# psoc6_01 register map
Vendor: Infineon Technologies; Series: PSOC6_01; File version: 1.0
CPU: CM4 r0p1, little endian, MPU, FPU, VTOR, 3 interrupt priority bits
Registers are 32-bit, read-write, reset 0x0 unless marked. A register's access mark holds for its fields unless they carry their own. Offsets are from the block's base; [hi:lo] are bit positions; 'fields as' and 'values as' point back to an identical list.

## CTBM0 — Continuous Time Block Mini
Base 0x41100000
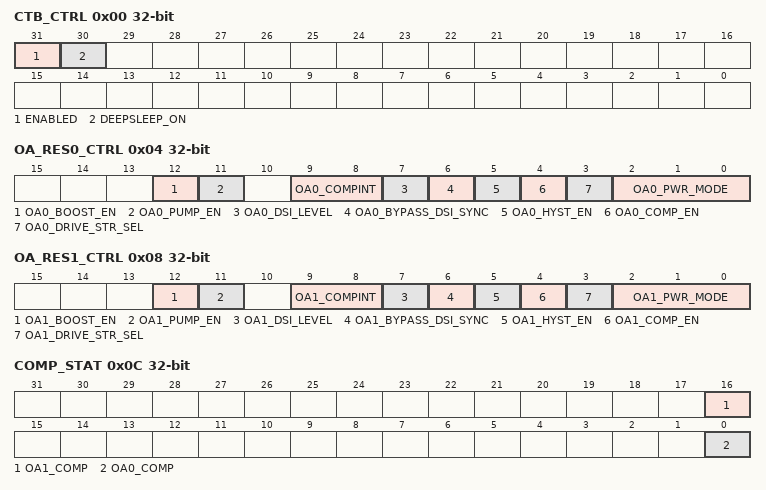
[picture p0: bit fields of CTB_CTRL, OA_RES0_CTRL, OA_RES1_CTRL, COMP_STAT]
0x00 CTB_CTRL — global CTB and power control
  [31] ENABLED — - 0: CTBm disabled (put analog in power down, open all switches) - 1: CTBm enabled
  [30] DEEPSLEEP_ON — - 0: CTBm is disabled during DeepSleep power mode - 1: CTBm remains enabled during DeepSleep power mode (if ENABLED=1)
0x04 OA_RES0_CTRL — Opamp0 and resistor0 control
  [12] OA0_BOOST_EN
  [11] OA0_PUMP_EN
  [9:8] OA0_COMPINT — Opamp comparator edge detect for interrupt and pulse mode of trigger
    0=DISABLE (Disabled, no interrupts will be detected); 1=RISING (Rising edge); 2=FALLING (Falling edge); 3=BOTH (Both rising and falling edges)
  [7] OA0_DSI_LEVEL — Opamp comparator trigger output level : 0=pulse, each time an edge is detected (see OA0_COMPINT) a pulse is sent out on trigger 1=level, trigger output is a synchronized version of the comparator output
  [6] OA0_BYPASS_DSI_SYNC — Opamp bypass comparator output synchronization for trigger output: 0=synchronize (level or pulse), 1=bypass (asynchronous output).
  [5] OA0_HYST_EN — Opamp hysteresis enable. See the device Datasheet for hysteresis specifications.
  [4] OA0_COMP_EN
  [3] OA0_DRIVE_STR_SEL — Opamp output drive strength: 0=1x, 1=10x. See the device Datasheet for exact current ranges and related specifications.This setting sets specific requirements for OA0_BOOST_EN and OA0_COMP_TRIM.
  [2:0] OA0_PWR_MODE — Opamp power level. Reduced power levels also reduce gain-bandwidth (GBW). See the 'Opamp Specifications' table in the device Datasheet for more details.
    0=OFF; 1=LOW (Low power mode (IDD: 350uA, GBW: 1MHz for both 1x/10x)); 2=MEDIUM (Medium power mode (IDD: 600uA, GBW: 3MHz for 1x & 2.5MHz for 10x)); 3=HIGH (High power mode for highest GBW (IDD: 1500uA, GBW: 8MHz for 1x & 6MHz for 10x)); 4=RSVD (N/A); 5=PS_LOW (Power Saver Low power mode (IDD: ~20uA with 1uA bias from AREF, GBW: ~100kHz for 1x/10x, offset correcting IDAC is disabled)); 6=PS_MEDIUM (Power Saver Medium power mode (IDD: ~40uA with 1uA bias from AREF, GBW: ~100kHz for 1x/10x, offset correcting IDAC is enabled)); 7=PS_HIGH (Power Saver Medium power mode (IDD: ~60uA with 1uA bias from AREF, GBW: ~200kHz for 1x/10x, offset correcting IDAC is enabled))
0x08 OA_RES1_CTRL — Opamp1 and resistor1 control
  [12] OA1_BOOST_EN
  [11] OA1_PUMP_EN
  [9:8] OA1_COMPINT — Opamp comparator edge detect for interrupt and pulse mode of trigger
    values as OA_RES0_CTRL.OA0_COMPINT
  [7] OA1_DSI_LEVEL — Opamp comparator trigger output level : 0=pulse, each time an edge is detected (see OA1_COMPINT) a pulse is sent out on trigger 1=level, trigger output is a synchronized version of the comparator output
  [6] OA1_BYPASS_DSI_SYNC — Opamp bypass comparator output synchronization for trigger output: 0=synchronize (level or pulse), 1=bypass (asynchronous output).
  [5] OA1_HYST_EN — Opamp hysteresis enable. See the device Datasheet for hysteresis specifications.
  [4] OA1_COMP_EN
  [3] OA1_DRIVE_STR_SEL — Opamp output drive strength: 0=1x, 1=10x. See the device Datasheet for exact current ranges and related specifications.This setting sets specific requirements for OA1_BOOST_EN and OA1_COMP_TRIM
  [2:0] OA1_PWR_MODE — Opamp power level. Reduced power levels also reduce gain-bandwidth (GBW). See the 'Opamp Specifications' table in the device Datasheet for more details.
0x0C COMP_STAT ro — Comparator status
  [16] OA1_COMP — Opamp1 current comparator status
  [0] OA0_COMP — Opamp0 current comparator status
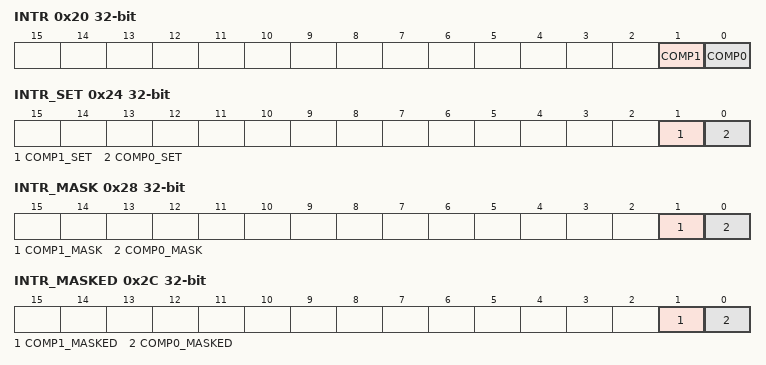
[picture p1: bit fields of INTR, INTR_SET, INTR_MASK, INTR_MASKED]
0x20 INTR — Interrupt request register
  [1] COMP1 — Comparator 1 Interrupt: hardware sets this interrupt when comparator 1 triggers. Write with '1' to clear bit.
  [0] COMP0 — Comparator 0 Interrupt: hardware sets this interrupt when comparator 0 triggers. Write with '1' to clear bit.
0x24 INTR_SET — Interrupt request set register
  [1] COMP1_SET — Write with '1' to set corresponding bit in interrupt request register.
  [0] COMP0_SET — Write with '1' to set corresponding bit in interrupt request register.
0x28 INTR_MASK — Interrupt request mask
  [1] COMP1_MASK — Mask bit for corresponding bit in interrupt request register.
  [0] COMP0_MASK — Mask bit for corresponding bit in interrupt request register.
0x2C INTR_MASKED ro — Interrupt request masked
  [1] COMP1_MASKED — Logical and of corresponding request and mask bits.
  [0] COMP0_MASKED — Logical and of corresponding request and mask bits.
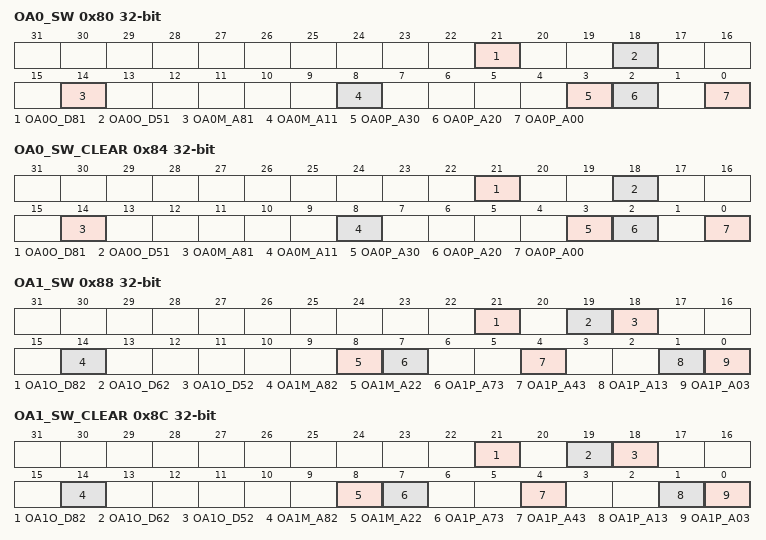
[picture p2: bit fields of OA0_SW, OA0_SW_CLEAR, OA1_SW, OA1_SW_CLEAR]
0x80 OA0_SW — Opamp0 switch control
  [21] OA0O_D81 — Switch that shorts Opamp's 1x and 10x outputs.
  [18] OA0O_D51 — Switch that connects Opamp's output to SARBUS 0.
  [14] OA0M_A81 — Switch that connects Opamp's inverting terminal to Opamp's output for follower mode.
  [8] OA0M_A11 — Switch that connects Opamp's inverting terminal to pin 1 of CTBm port .
  [3] OA0P_A30 — Switch that connects Opamp's non-inverting terminal to pin 6 of CTBm port. Note that this bus can have additional connections to or from the CTDAC. See the Architecture TRM for details.
  [2] OA0P_A20 — Switch that connects Opamp's non-inverting terminal to pin 0 of CTBm port. See the device Datasheet for the location of CTBm port.
  [0] OA0P_A00 — Switch that connects Opamp's non-inverting terminal to AMUXBUS A.
0x84 OA0_SW_CLEAR — Opamp0 switch control clear
  [21] OA0O_D81 — see corresponding bit in OA0_SW
  [18] OA0O_D51 — see corresponding bit in OA0_SW
  [14] OA0M_A81 — see corresponding bit in OA0_SW
  [8] OA0M_A11 — see corresponding bit in OA0_SW
  [3] OA0P_A30 — see corresponding bit in OA0_SW
  [2] OA0P_A20 — see corresponding bit in OA0_SW
  [0] OA0P_A00 — see corresponding bit in OA0_SW
0x88 OA1_SW — Opamp1 switch control
  [21] OA1O_D82 — Switch that shorts Opamp's 1x and 10x outputs.
  [19] OA1O_D62 — Switch that connects Opamp's output to SARBUS 1.
  [18] OA1O_D52 — Switch that connects Opamp's output to SARBUS 0.
  [14] OA1M_A82 — Switch that connects Opamp's inverting terminal to Opamp's output for follower mode.
  [8] OA1M_A22 — Switch that connects Opamp's inverting terminal to pin 4 of CTBm port.
  [7] OA1P_A73 — Switch that connects Opamp's non-inverting terminal to VREF.
  [4] OA1P_A43 — Switch that connects Opamp's non-inverting terminal to pin 7 of CTBm port.
  [1] OA1P_A13 — Switch that connects Opamp's non-inverting terminal to pin 5 of CTBm port. See the device Datasheet for the location of CTBm port.
  [0] OA1P_A03 — Switch that connects Opamp's non-inverting terminal to AMUXBUS B.
0x8C OA1_SW_CLEAR — Opamp1 switch control clear
  [21] OA1O_D82 — see corresponding bit in OA1_SW
  [19] OA1O_D62 — see corresponding bit in OA1_SW
  [18] OA1O_D52 — see corresponding bit in OA1_SW
  [14] OA1M_A82 — see corresponding bit in OA1_SW
  [8] OA1M_A22 — see corresponding bit in OA1_SW
  [7] OA1P_A73 — see corresponding bit in OA1_SW
  [4] OA1P_A43 — see corresponding bit in OA1_SW
  [1] OA1P_A13 — see corresponding bit in OA1_SW
  [0] OA1P_A03 — see corresponding bit in OA1_SW
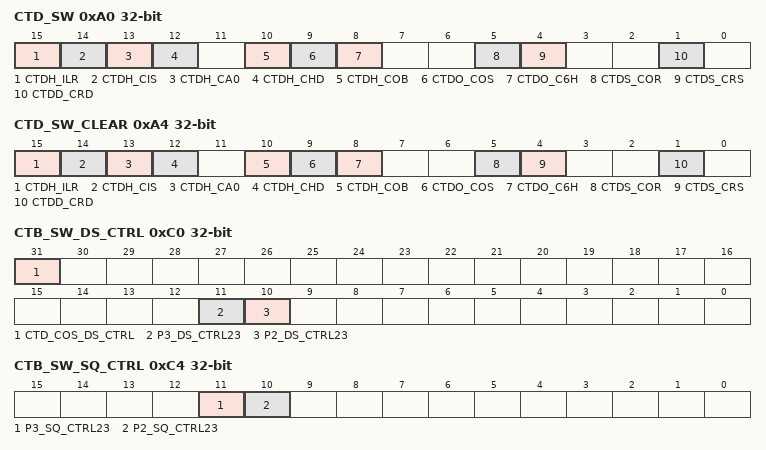
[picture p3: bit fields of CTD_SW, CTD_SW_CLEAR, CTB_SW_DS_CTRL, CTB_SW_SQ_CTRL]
0xA0 CTD_SW — CTDAC connection switch control
  [15] CTDH_ILR — Switch that shorts Opamp0's inverting and non-inverting inputs to reduce hold capacitor leakage.
  [14] CTDH_CIS — Switch that isolates hold capacitor from other inputs connected to Opamp0's non-inverting input.
  [13] CTDH_CA0 — Switch that connects hold capacitor to Opamp0's non-inverting input.
  [12] CTDH_CHD
  [10] CTDH_COB — Switch that connects hold capacitor to Opamp0's output. Used during hold mode in Sample and Hold operation.
  [9] CTDO_COS — Switch that connects ctdvout to the internal hold capacitor (Sampling Switch). Note this switch will temporarily be opened for deglitching if CTDAC.DEGLITCH_COS is set.
  [8] CTDO_C6H — Switch that connects pin 6 of the CTBm port to ctdvout (CTDAC Vout). See the device Datasheet for the location of CTBm port.
  [5] CTDS_COR — Switch that connects Opamp1's inverting input to ctdvout (CTDAC Vout).
  [4] CTDS_CRS — Switch that connects Opamp1's inverting input to ctdrefsense (CTDAC Reference Sense).
  [1] CTDD_CRD — Switch that connects Opamp1's output to ctdrefdrive (CTDAC Reference Drive).
0xA4 CTD_SW_CLEAR — CTDAC connection switch control clear
  [15] CTDH_ILR — see corresponding bit in CTD_SW
  [14] CTDH_CIS — see corresponding bit in CTD_SW
  [13] CTDH_CA0 — see corresponding bit in CTD_SW
  [12] CTDH_CHD — see corresponding bit in CTD_SW
  [10] CTDH_COB — see corresponding bit in CTD_SW
  [9] CTDO_COS — see corresponding bit in CTD_SW
  [8] CTDO_C6H — see corresponding bit in CTD_SW
  [5] CTDS_COR — see corresponding bit in CTD_SW
  [4] CTDS_CRS — see corresponding bit in CTD_SW
  [1] CTDD_CRD — see corresponding bit in CTD_SW
0xC0 CTB_SW_DS_CTRL — CTB bus switch control
  [31] CTD_COS_DS_CTRL, [11] P3_DS_CTRL23, [10] P2_DS_CTRL23
0xC4 CTB_SW_SQ_CTRL — CTB bus switch Sar Sequencer control
  [11] P3_SQ_CTRL23 — for D52, D62
  [10] P2_SQ_CTRL23 — for D51
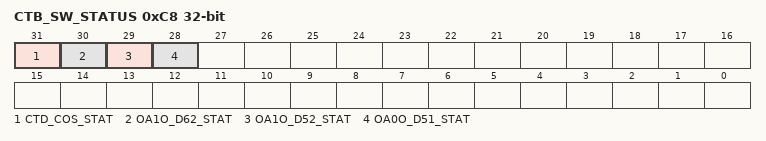
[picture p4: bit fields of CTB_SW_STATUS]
0xC8 CTB_SW_STATUS ro — CTB bus switch control status
  [31] CTD_COS_STAT — see COS bit in CTD_SW
  [30] OA1O_D62_STAT — see OA1O_D62 bit in OA1_SW
  [29] OA1O_D52_STAT — see OA1O_D52 bit in OA1_SW
  [28] OA0O_D51_STAT — see OA0O_D51 bit in OA0_SW
0xF00 OA0_OFFSET_TRIM — Opamp0 trim control
  [5:0] OA0_OFFSET_TRIM — Opamp0 offset trim
0xF04 OA0_SLOPE_OFFSET_TRIM — Opamp0 trim control
  [5:0] OA0_SLOPE_OFFSET_TRIM — Opamp0 slope offset drift trim
0xF08 OA0_COMP_TRIM — Opamp0 trim control
  [1:0] OA0_COMP_TRIM — Opamp0 Compensation Capacitor Trim. Value depends on the drive strength setting - 1x mode: set to 01; 10x mode: set to 11
0xF0C OA1_OFFSET_TRIM — Opamp1 trim control
  [5:0] OA1_OFFSET_TRIM — Opamp1 offset trim
0xF10 OA1_SLOPE_OFFSET_TRIM — Opamp1 trim control
  [5:0] OA1_SLOPE_OFFSET_TRIM — Opamp1 slope offset drift trim
0xF14 OA1_COMP_TRIM — Opamp1 trim control
  [1:0] OA1_COMP_TRIM — Opamp1 Compensation Capacitor Trim. Value depends on the drive strength setting - 1x mode: set to 01; 10x mode: set to 11
